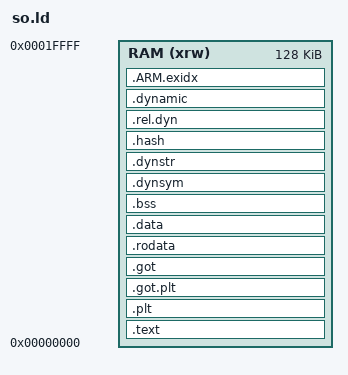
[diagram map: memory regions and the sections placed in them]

MEMORY
{
    RAM (xrw)  : ORIGIN = 0x00000000, LENGTH = 0x20000     /* 128K, text/data/bss/heap/stack */
}

_SO_text = (SIZEOF(.text) + (0x4 -1)) & (~(0x4 -1));
_SO_plt  = (SIZEOF(.plt) + (0x4 -1)) & (~(0x4 -1));
_SO_got_plt = (SIZEOF(.got.plt) + (0x4 -1)) & (~(0x4 -1));
_SO_got = (SIZEOF(.got) + (0x4 -1)) & (~(0x4 -1));
_SO_rodata = (SIZEOF(.rodata) + (0x4 -1)) & (~(0x4 -1));
_SO_data = (SIZEOF(.data) + (0x4 -1)) & (~(0x4 -1));
_SO_bss = (SIZEOF(.bss) + (0x4 -1)) & (~(0x4 -1));


SECTIONS
{
    .text : ALIGN(4)
    {
        *(.dummy_front)
        
        *(.text .text.*)                                        /* c library code here */

        /*
         * Stub sections generated by the linker, to glue together
         * ARM and Thumb code. .glue_7 is used for ARM code calling
         * Thumb code, and .glue_7t is used for Thumb code calling
         * ARM code. Apparently always generated by the linker, for some
         * architectures, so better leave them here.
         */
        *(.glue_7)
        *(.glue_7t)

    } >RAM

    .plt : ALIGN(4)
    {
        *(.plt)
    } >RAM

    .got.plt : ALIGN(4)
    {
        *(.got.plt)
    } >RAM

    .got : ALIGN(4)
    {
        *(.got)
    } >RAM

    .rodata : ALIGN(4)
    {
        *(.rodata .rodata.* .constdata .constdata.*)            /* c library rodata here */
        . = ALIGN(4);
    } >RAM

    .data : ALIGN(4)
    {
        FILL(0xFF)
        /* This is used by the startup code to initialise the .data section */
        __data_start__ = . ;

        *(.data_begin .data_begin.*)

        *(.data .data.*)
        
        *(.data_end .data_end.*)
        . = ALIGN(4);

        /* This is used by the startup code to initialise the .data section */
        __data_end__ = . ;

    } >RAM

    /* The primary uninitialised data section. */
    .bss (NOLOAD) : ALIGN(4)
    {
        __bss_start__ = .;      /* standard newlib definition */
        *(.bss_begin .bss_begin.*)

        *(.bss .bss.*)

        *(.bss_end .bss_end.*)
        __bss_end__ = .;        /* standard newlib definition */

        *(COMMON)
        . = ALIGN(4);
        __bss_actual_end__ = .; /* actually bss end */
    } >RAM

    .dynsym : ALIGN(4)
    {
        *(.dynsym)
    } >RAM

    .dynstr : ALIGN(4)
    {
        *(.dynstr)
    } >RAM

    .hash : ALIGN(4)
    {
        *(.hash)
    } >RAM

    .rel.dyn : ALIGN(4)
    {
        *(.rel.got)
        *(.rel.plt)
        *(.rel.iplt)
    } >RAM

    .dynamic : ALIGN(4)
    {
        *(.dynamic)
    } >RAM

    .ARM.exidx : ALIGN(4)
   	{
       *(.ARM.exidx* .gnu.linkonce.armexidx.*)
   	} > RAM
}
